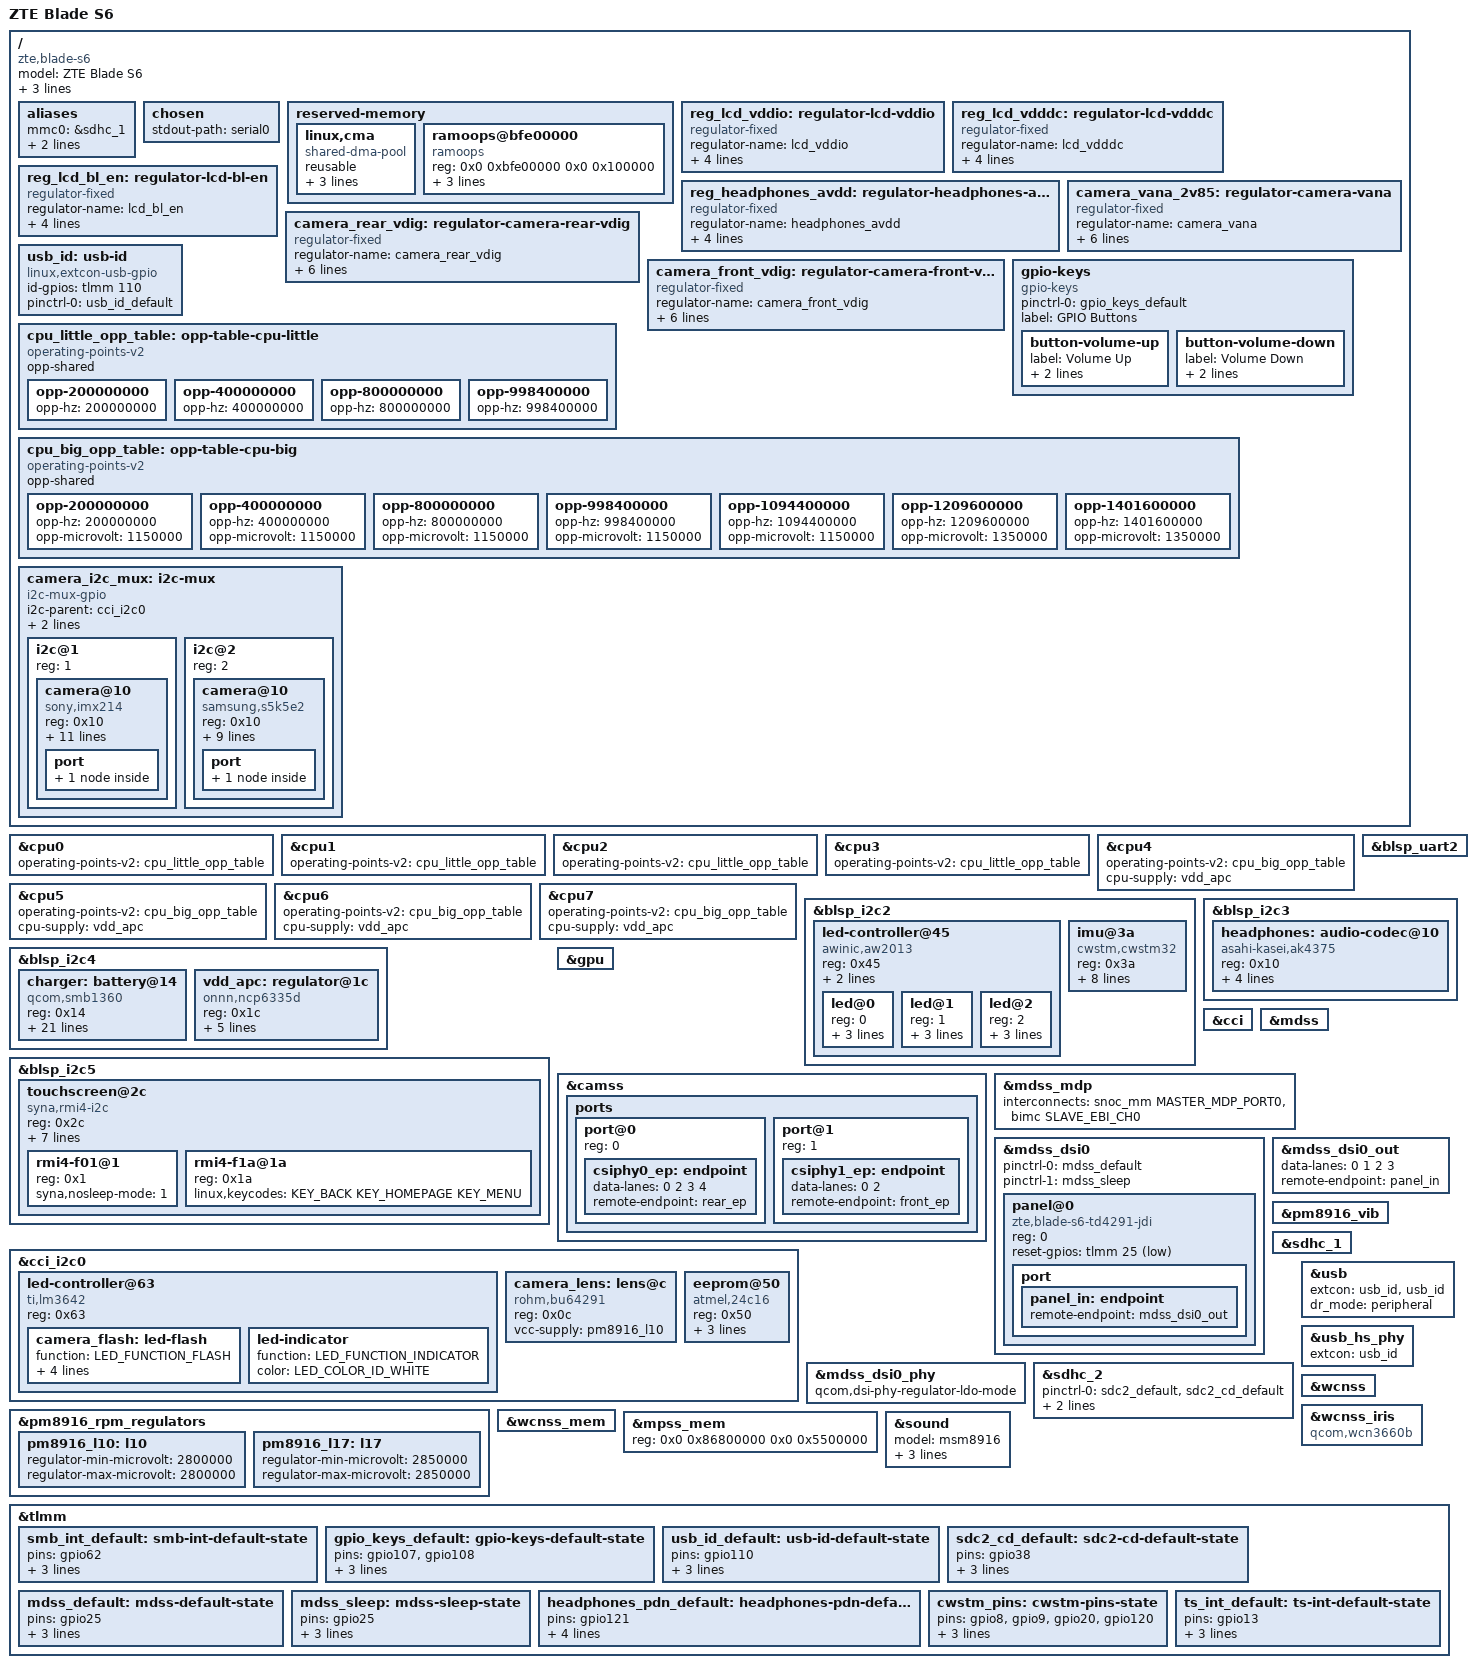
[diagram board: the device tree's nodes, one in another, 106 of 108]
// SPDX-License-Identifier: GPL-2.0-only
// ZTE Blade S6 (P839F30) - mainline device tree

/dts-v1/;

#include "msm8939-pm8916.dtsi"
#include "msm8916-modem-qdsp6.dtsi"
#include <dt-bindings/arm/qcom,ids.h>
#include <dt-bindings/gpio/gpio.h>
#include <dt-bindings/input/input.h>
#include <dt-bindings/leds/common.h>
#include <dt-bindings/interrupt-controller/irq.h>

/ {
	model = "ZTE Blade S6";
	compatible = "zte,blade-s6", "qcom,msm8939";
	chassis-type = "handset";

	/* Match lk2nd msm8939-zte-blade-s6.dts (MSM8939 MTP board 8 rev 1). */
	qcom,msm-id = <QCOM_ID_MSM8939 0>;
	qcom,board-id = <8 1>;

	aliases {
		mmc0 = &sdhc_1; /* eMMC */
		mmc1 = &sdhc_2; /* SD card */
		serial0 = &blsp_uart2;
	};

	chosen {
		stdout-path = "serial0";
	};

	reserved-memory {
		#address-cells = <2>;
		#size-cells = <2>;
		ranges;

		/* Full-resolution camera frames need contiguous buffers */
		linux,cma {
			compatible = "shared-dma-pool";
			reusable;
			size = <0x0 0x0c000000>;
			alignment = <0x0 0x00400000>;
			linux,cma-default;
		};

		ramoops@bfe00000 {
			compatible = "ramoops";
			reg = <0x0 0xbfe00000 0x0 0x100000>;
			console-size = <0x40000>;
			record-size = <0x10000>;
			pmsg-size = <0x20000>;
		};
	};

	reg_lcd_vddio: regulator-lcd-vddio {
		compatible = "regulator-fixed";
		regulator-name = "lcd_vddio";
		gpio = <&tlmm 16 GPIO_ACTIVE_HIGH>;
		enable-active-high;
		regulator-always-on;
		regulator-boot-on;
	};

	reg_lcd_vdddc: regulator-lcd-vdddc {
		compatible = "regulator-fixed";
		regulator-name = "lcd_vdddc";
		gpio = <&tlmm 112 GPIO_ACTIVE_HIGH>;
		enable-active-high;
		regulator-always-on;
		regulator-boot-on;
	};

	reg_lcd_bl_en: regulator-lcd-bl-en {
		compatible = "regulator-fixed";
		regulator-name = "lcd_bl_en";
		gpio = <&tlmm 98 GPIO_ACTIVE_HIGH>;
		enable-active-high;
		regulator-always-on;
		regulator-boot-on;
	};

	reg_headphones_avdd: regulator-headphones-avdd {
		compatible = "regulator-fixed";
		regulator-name = "headphones_avdd";
		regulator-min-microvolt = <1800000>;
		regulator-max-microvolt = <1800000>;
		gpio = <&tlmm 21 GPIO_ACTIVE_HIGH>;
		enable-active-high;
	};

	/*
	 * The camera modules take their analog and digital rails through load
	 * switches on the board, not straight off the PMIC: qcom,gpio-vana and
	 * qcom,gpio-vdig in the vendor tree. VANA is shared by both sensors.
	 */
	camera_vana_2v85: regulator-camera-vana {
		compatible = "regulator-fixed";
		regulator-name = "camera_vana";
		regulator-min-microvolt = <2850000>;
		regulator-max-microvolt = <2850000>;
		gpio = <&tlmm 69 GPIO_ACTIVE_HIGH>;
		enable-active-high;
		startup-delay-us = <1000>;
		vin-supply = <&pm8916_l17>;
	};

	camera_rear_vdig: regulator-camera-rear-vdig {
		compatible = "regulator-fixed";
		regulator-name = "camera_rear_vdig";
		regulator-min-microvolt = <1800000>;
		regulator-max-microvolt = <1800000>;
		gpio = <&tlmm 109 GPIO_ACTIVE_HIGH>;
		enable-active-high;
		startup-delay-us = <1000>;
		vin-supply = <&pm8916_s4>;
	};

	camera_front_vdig: regulator-camera-front-vdig {
		compatible = "regulator-fixed";
		regulator-name = "camera_front_vdig";
		regulator-min-microvolt = <1800000>;
		regulator-max-microvolt = <1800000>;
		gpio = <&tlmm 17 GPIO_ACTIVE_HIGH>;
		enable-active-high;
		startup-delay-us = <1000>;
		vin-supply = <&pm8916_s4>;
	};

	gpio-keys {
		compatible = "gpio-keys";
		pinctrl-0 = <&gpio_keys_default>;
		pinctrl-names = "default";
		label = "GPIO Buttons";

		button-volume-up {
			label = "Volume Up";
			gpios = <&tlmm 107 GPIO_ACTIVE_LOW>;
			linux,code = <KEY_VOLUMEUP>;
		};

		button-volume-down {
			label = "Volume Down";
			gpios = <&tlmm 108 GPIO_ACTIVE_LOW>;
			linux,code = <KEY_VOLUMEDOWN>;
		};
	};

	usb_id: usb-id {
		compatible = "linux,extcon-usb-gpio";
		id-gpios = <&tlmm 110 GPIO_ACTIVE_HIGH>;
		pinctrl-0 = <&usb_id_default>;
		pinctrl-names = "default";
	};

	/* 200/400/800 MHz are GPLL0-derived; 998.4 MHz and up are a53pll rates */
	cpu_little_opp_table: opp-table-cpu-little {
		compatible = "operating-points-v2";
		opp-shared;

		opp-200000000 { opp-hz = /bits/ 64 <200000000>; };
		opp-400000000 { opp-hz = /bits/ 64 <400000000>; };
		opp-800000000 { opp-hz = /bits/ 64 <800000000>; };
		opp-998400000 { opp-hz = /bits/ 64 <998400000>; };
	};

	cpu_big_opp_table: opp-table-cpu-big {
		compatible = "operating-points-v2";
		opp-shared;

		/* opp-microvolt = the downstream CPR open-loop corner: 1.15 V Nominal, 1.35 V Turbo */
		opp-200000000  { opp-hz = /bits/ 64 <200000000>;  opp-microvolt = <1150000>; };
		opp-400000000  { opp-hz = /bits/ 64 <400000000>;  opp-microvolt = <1150000>; };
		opp-800000000  { opp-hz = /bits/ 64 <800000000>;  opp-microvolt = <1150000>; };
		opp-998400000  { opp-hz = /bits/ 64 <998400000>;  opp-microvolt = <1150000>; };
		opp-1094400000 { opp-hz = /bits/ 64 <1094400000>; opp-microvolt = <1150000>; };
		opp-1209600000 { opp-hz = /bits/ 64 <1209600000>; opp-microvolt = <1350000>; };
		opp-1401600000 { opp-hz = /bits/ 64 <1401600000>; opp-microvolt = <1350000>; };
	};
};

/* LITTLE cluster: apcs1 / a53pll_c1 */
&cpu0 { operating-points-v2 = <&cpu_little_opp_table>; };
&cpu1 { operating-points-v2 = <&cpu_little_opp_table>; };
&cpu2 { operating-points-v2 = <&cpu_little_opp_table>; };
&cpu3 { operating-points-v2 = <&cpu_little_opp_table>; };

/* big cluster: apcs0 / a53pll_c0; cpu-supply scales VDD_APC with frequency */
&cpu4 { operating-points-v2 = <&cpu_big_opp_table>; cpu-supply = <&vdd_apc>; };
&cpu5 { operating-points-v2 = <&cpu_big_opp_table>; cpu-supply = <&vdd_apc>; };
&cpu6 { operating-points-v2 = <&cpu_big_opp_table>; cpu-supply = <&vdd_apc>; };
&cpu7 { operating-points-v2 = <&cpu_big_opp_table>; cpu-supply = <&vdd_apc>; };

&blsp_uart2 {
	status = "okay";
};

/* CyWee STM32 sensor hub: accel/gyro/magn/ALS/proximity behind an I2C MCU */
&blsp_i2c2 {
	status = "okay";

	led-controller@45 {
		compatible = "awinic,aw2013";
		reg = <0x45>;
		#address-cells = <1>;
		#size-cells = <0>;

		vcc-supply = <&pm8916_l17>;
		vio-supply = <&pm8916_l6>;

		led@0 {
			reg = <0>;
			led-max-microamp = <5000>;
			function = LED_FUNCTION_INDICATOR;
			color = <LED_COLOR_ID_RED>;
		};

		led@1 {
			reg = <1>;
			led-max-microamp = <5000>;
			function = LED_FUNCTION_INDICATOR;
			color = <LED_COLOR_ID_GREEN>;
		};

		led@2 {
			reg = <2>;
			led-max-microamp = <5000>;
			function = LED_FUNCTION_INDICATOR;
			color = <LED_COLOR_ID_BLUE>;
		};
	};

	imu@3a {
		compatible = "cwstm,cwstm32";
		reg = <0x3a>;
		vdd-supply = <&pm8916_l17>;
		vio-supply = <&pm8916_l6>;
		interrupts-extended = <&tlmm 9 IRQ_TYPE_EDGE_RISING>;
		reset-gpios = <&tlmm 20 GPIO_ACTIVE_HIGH>;
		boot-gpios = <&tlmm 8 GPIO_ACTIVE_HIGH>;
		wakeup-gpios = <&tlmm 120 GPIO_ACTIVE_HIGH>;
		pinctrl-0 = <&cwstm_pins>;
		pinctrl-names = "default";
	};
};

&blsp_i2c3 {
	status = "okay";

	headphones: audio-codec@10 {
		compatible = "asahi-kasei,ak4375";
		reg = <0x10>;

		avdd-supply = <&reg_headphones_avdd>;
		tvdd-supply = <&pm8916_l6>;
		pdn-gpios = <&tlmm 121 GPIO_ACTIVE_HIGH>;

		pinctrl-0 = <&headphones_pdn_default>;
		pinctrl-names = "default";

		#sound-dai-cells = <0>;
	};
};

/* External VDD_APC buck, shared by both clusters; floored at the 1.15 V Nominal corner */
&blsp_i2c4 {
	status = "okay";

	charger: battery@14 {
		compatible = "qcom,smb1360";
		reg = <0x14>;

		interrupts-extended = <&tlmm 62 IRQ_TYPE_LEVEL_LOW>;
		pinctrl-0 = <&smb_int_default>;
		pinctrl-names = "default";

		qcom,float-voltage-mv = <4350>;
		qcom,iterm-ma = <125>;
		qcom,charging-timeout = <1536>;
		qcom,recharge-thresh-mv = <200>;
		qcom,chg-inhibit-disabled;
		qcom,shdn-after-pwroff;

		qcom,fg-batt-capacity-mah = <2400>;
		qcom,fg-cc-soc-coeff = <0x82d4>;
		qcom,fg-cutoff-voltage-mv = <3500>;
		qcom,fg-voltage-empty-mv = <3400>;
		qcom,fg-iterm-ma = <150>;
		qcom,fg-auto-recharge-soc = <99>;
		qcom,thermistor-c1-coeff = <0x85ec>;

		qcom,otp-hard-jeita-config;
		qcom,otp-hot-bat-decidegc = <590>;
		qcom,otp-cold-bat-decidegc = <10>;
		qcom,warm-bat-decidegc = <450>;
		qcom,cool-bat-decidegc = <100>;
	};

	vdd_apc: regulator@1c {
		compatible = "onnn,ncp6335d";
		reg = <0x1c>;
		regulator-name = "vdd_apc";
		regulator-min-microvolt = <1150000>;
		regulator-max-microvolt = <1350000>;
		regulator-always-on;
		regulator-boot-on;
	};
};

/* Synaptics TD4291 TDDI; reset is the shared LCD reset gpio25, owned by panel@0 */
&blsp_i2c5 {
	status = "okay";

	touchscreen@2c {
		compatible = "syna,rmi4-i2c";
		reg = <0x2c>;
		interrupts-extended = <&tlmm 13 IRQ_TYPE_LEVEL_LOW>;
		vdd-supply = <&reg_lcd_vdddc>;
		vio-supply = <&reg_lcd_vddio>;
		pinctrl-0 = <&ts_int_default>;
		pinctrl-names = "default";
		#address-cells = <1>;
		#size-cells = <0>;

		syna,startup-delay-ms = <100>;
		syna,reset-delay-ms = <300>;

		rmi4-f01@1 {
			reg = <0x1>;
			syna,nosleep-mode = <1>;
		};

		rmi4-f1a@1a {
			reg = <0x1a>;
			/* capacitive nav keys: Back, Home, Menu */
			linux,keycodes = <KEY_BACK KEY_HOMEPAGE KEY_MENU>;
		};
	};
};

&gpu {
	status = "okay";
};

&camss {
	status = "okay";

	ports {
		port@0 {
			reg = <0>;
			csiphy0_ep: endpoint {
				data-lanes = <0 2 3 4>;
				remote-endpoint = <&rear_ep>;
			};
		};

		port@1 {
			reg = <1>;

			csiphy1_ep: endpoint {
				data-lanes = <0 2>;
				remote-endpoint = <&front_ep>;
			};
		};
	};
};

&cci {
	status = "okay";
};

&cci_i2c0 {
	#address-cells = <1>;
	#size-cells = <0>;

	/* camera flash / torch */
	led-controller@63 {
		compatible = "ti,lm3642";
		reg = <0x63>;

		camera_flash: led-flash {
			function = LED_FUNCTION_FLASH;
			color = <LED_COLOR_ID_WHITE>;
			led-max-microamp = <375000>;
			flash-max-microamp = <1500000>;
			flash-max-timeout-us = <800000>;
		};

		led-indicator {
			function = LED_FUNCTION_INDICATOR;
			color = <LED_COLOR_ID_WHITE>;
		};
	};

	/* autofocus actuator on the rear camera module */
	camera_lens: lens@c {
		compatible = "rohm,bu64291";
		reg = <0x0c>;
		vcc-supply = <&pm8916_l10>;
	};

	eeprom@50 {
		compatible = "atmel,24c16";
		reg = <0x50>;
		pagesize = <16>;
		read-only;
		vcc-supply = <&pm8916_l6>;
	};
};

/ {
	/*
	 * Both sensors answer at 0x10 and are told apart by their reset
	 * lines: the module held in reset releases the bus. Selecting a
	 * channel releases that sensor and asserts the other one's reset.
	 */
	camera_i2c_mux: i2c-mux {
		compatible = "i2c-mux-gpio";
		#address-cells = <1>;
		#size-cells = <0>;

		i2c-parent = <&cci_i2c0>;
		mux-gpios = <&tlmm 35 GPIO_ACTIVE_HIGH>, <&tlmm 28 GPIO_ACTIVE_HIGH>;
		settle-time-us = <30000>;

		i2c@1 {
			reg = <1>;
			#address-cells = <1>;
			#size-cells = <0>;

			/* rear camera: Sony IMX214, 13 MP */
			camera@10 {
				compatible = "sony,imx214";
				reg = <0x10>;

				pinctrl-0 = <&camera_rear_default>;
				pinctrl-names = "default";

				clocks = <&gcc GCC_CAMSS_MCLK0_CLK>;
				clock-names = "xclk";
				assigned-clocks = <&gcc GCC_CAMSS_MCLK0_CLK>;
				assigned-clock-rates = <24000000>;

				vdddo-supply = <&pm8916_l6>;
				vdda-supply = <&camera_vana_2v85>;
				vddd-supply = <&camera_rear_vdig>;

				lens-focus = <&camera_lens>;
				flash-leds = <&camera_flash>;

				orientation = <1>;
				rotation = <90>;

				port {
					rear_ep: endpoint {
						data-lanes = <1 2 3 4>;
						link-frequencies = /bits/ 64 <600000000>;
						remote-endpoint = <&csiphy0_ep>;
					};
				};
			};
		};

		i2c@2 {
			reg = <2>;
			#address-cells = <1>;
			#size-cells = <0>;

			/* front camera: Samsung S5K5E2, 5 MP */
			camera@10 {
				compatible = "samsung,s5k5e2";
				reg = <0x10>;

				pinctrl-0 = <&camera_front_default>;
				pinctrl-names = "default";

				clocks = <&gcc GCC_CAMSS_MCLK1_CLK>;
				clock-names = "xclk";
				assigned-clocks = <&gcc GCC_CAMSS_MCLK1_CLK>;
				assigned-clock-rates = <24000000>;

				vddio-supply = <&pm8916_l6>;
				vdda-supply = <&camera_vana_2v85>;
				vddd-supply = <&camera_front_vdig>;

				orientation = <0>;
				rotation = <270>;

				port {
					front_ep: endpoint {
						data-lanes = <1 2>;
						link-frequencies = /bits/ 64 <448000000>;
						remote-endpoint = <&csiphy1_ep>;
					};
				};
			};
		};
	};
};


&mdss {
	status = "okay";
};

&mdss_mdp {
	interconnects = <&snoc_mm MASTER_MDP_PORT0 &bimc SLAVE_EBI_CH0>;
	interconnect-names = "mdp0-mem";
};

&mdss_dsi0 {
	pinctrl-0 = <&mdss_default>;
	pinctrl-1 = <&mdss_sleep>;
	pinctrl-names = "default", "sleep";
	status = "okay";

	panel@0 {
		compatible = "zte,blade-s6-td4291-jdi";
		reg = <0>;
		reset-gpios = <&tlmm 25 GPIO_ACTIVE_LOW>;

		port {
			panel_in: endpoint {
				remote-endpoint = <&mdss_dsi0_out>;
			};
		};
	};
};

&mdss_dsi0_out {
	data-lanes = <0 1 2 3>;
	remote-endpoint = <&panel_in>;
};

&mdss_dsi0_phy {
	qcom,dsi-phy-regulator-ldo-mode;
	status = "okay";
};

&pm8916_rpm_regulators {
	/* VCM autofocus actuator on the rear camera module */
	pm8916_l10: l10 {
		regulator-min-microvolt = <2800000>;
		regulator-max-microvolt = <2800000>;
	};

	pm8916_l17: l17 {
		regulator-min-microvolt = <2850000>;
		regulator-max-microvolt = <2850000>;
	};
};

&pm8916_vib {
	status = "okay";
};

&sdhc_1 {
	status = "okay";
};

&sdhc_2 {
	pinctrl-0 = <&sdc2_default &sdc2_cd_default>;
	pinctrl-1 = <&sdc2_sleep &sdc2_cd_default>;
	pinctrl-names = "default", "sleep";
	cd-gpios = <&tlmm 38 GPIO_ACTIVE_LOW>;
	status = "okay";
};

&usb {
	extcon = <&usb_id>, <&usb_id>;
	dr_mode = "peripheral";
	status = "okay";
};

&usb_hs_phy {
	extcon = <&usb_id>;
};

&wcnss {
	status = "okay";
};

&wcnss_iris {
	compatible = "qcom,wcn3660b";
};

&wcnss_mem {
	status = "okay";
};

/* device-specific size for the SoC's size-0 mpss_mem (0x5500000 = downstream modem_adsp) */
&mpss_mem {
	reg = <0x0 0x86800000 0x0 0x5500000>;
};

&sound {
	/* "msm8916" so the generic msm8916 alsa-ucm-conf profile matches this card */
	model = "msm8916";
	audio-routing =
		"AMIC1", "MIC BIAS External1",
		"AMIC2", "MIC BIAS Internal2",
		"AMIC3", "MIC BIAS External1";
};

&tlmm {
	smb_int_default: smb-int-default-state {
		pins = "gpio62";
		function = "gpio";
		drive-strength = <2>;
		bias-pull-up;
	};

	gpio_keys_default: gpio-keys-default-state {
		pins = "gpio107", "gpio108";
		function = "gpio";
		drive-strength = <2>;
		bias-pull-up;
	};

	usb_id_default: usb-id-default-state {
		pins = "gpio110";
		function = "gpio";
		drive-strength = <8>;
		bias-pull-up;
	};

	sdc2_cd_default: sdc2-cd-default-state {
		pins = "gpio38";
		function = "gpio";
		drive-strength = <2>;
		bias-disable;
	};

	mdss_default: mdss-default-state {
		pins = "gpio25";
		function = "gpio";
		drive-strength = <8>;
		bias-disable;
	};

	mdss_sleep: mdss-sleep-state {
		pins = "gpio25";
		function = "gpio";
		drive-strength = <2>;
		bias-pull-down;
	};

	headphones_pdn_default: headphones-pdn-default-state {
		pins = "gpio121";
		function = "gpio";

		drive-strength = <16>;
		bias-disable;
		output-low;
	};

	cwstm_pins: cwstm-pins-state {
		pins = "gpio8", "gpio9", "gpio20", "gpio120";
		function = "gpio";
		drive-strength = <2>;
		bias-disable;
	};

	ts_int_default: ts-int-default-state {
		pins = "gpio13";
		function = "gpio";
		drive-strength = <2>;
		bias-pull-up;
	};
};
